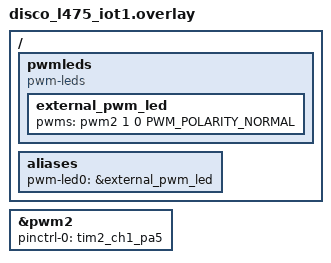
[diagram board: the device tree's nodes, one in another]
/*
 * SPDX-License-Identifier: MIT
 *
 * Copyright (c) 2021 Planet Innovation
 */

/ {
	pwmleds {
		compatible = "pwm-leds";
		external_pwm_led: external_pwm_led {
			pwms = <&pwm2 1 0 PWM_POLARITY_NORMAL>;
		};
	};

	aliases {
		pwm-led0 = &external_pwm_led;
	};

};


&pwm2 {
  pinctrl-0 = <&tim2_ch1_pa5>;
};
